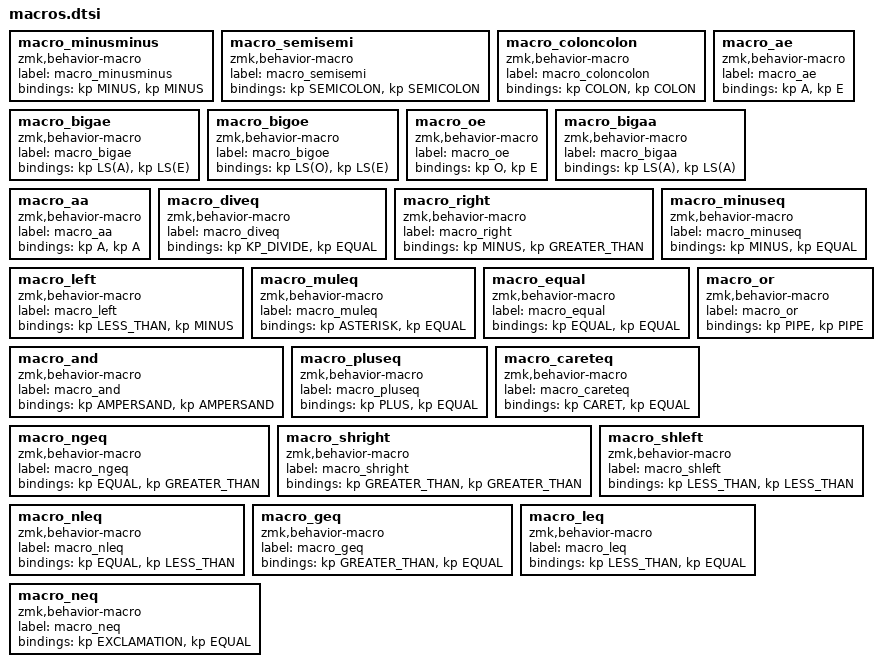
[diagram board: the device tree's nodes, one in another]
macro_minusminus: macro_minusminus{
compatible = "zmk,behavior-macro";
label = "macro_minusminus";
#binding-cells = <0>;
bindings = <&kp MINUS>, <&kp MINUS>;
};
macro_semisemi: macro_semisemi{
compatible = "zmk,behavior-macro";
label = "macro_semisemi";
#binding-cells = <0>;
bindings = <&kp SEMICOLON>, <&kp SEMICOLON>;
};
macro_coloncolon: macro_coloncolon{
compatible = "zmk,behavior-macro";
label = "macro_coloncolon";
#binding-cells = <0>;
bindings = <&kp COLON>, <&kp COLON>;
};
macro_bigae: macro_bigae{
compatible = "zmk,behavior-macro";
label = "macro_bigae";
#binding-cells = <0>;
bindings = <&kp LS(A)>, <&kp LS(E)>;
};
macro_ae: macro_ae{
compatible = "zmk,behavior-macro";
label = "macro_ae";
#binding-cells = <0>;
bindings = <&kp A>, <&kp E>;
};
macro_bigoe: macro_bigoe{
compatible = "zmk,behavior-macro";
label = "macro_bigoe";
#binding-cells = <0>;
bindings = <&kp LS(O)>, <&kp LS(E)>;
};
macro_oe: macro_oe{
compatible = "zmk,behavior-macro";
label = "macro_oe";
#binding-cells = <0>;
bindings = <&kp O>, <&kp E>;
};
macro_bigaa: macro_bigaa{
compatible = "zmk,behavior-macro";
label = "macro_bigaa";
#binding-cells = <0>;
bindings = <&kp LS(A)>, <&kp LS(A)>;
};
macro_aa: macro_aa{
compatible = "zmk,behavior-macro";
label = "macro_aa";
#binding-cells = <0>;
bindings = <&kp A>, <&kp A>;
};
macro_diveq: macro_diveq{
compatible = "zmk,behavior-macro";
label = "macro_diveq";
#binding-cells = <0>;
bindings = <&kp KP_DIVIDE>, <&kp EQUAL>;
};
macro_right: macro_right{
compatible = "zmk,behavior-macro";
label = "macro_right";
#binding-cells = <0>;
bindings = <&kp MINUS>, <&kp GREATER_THAN>;
};
macro_left: macro_left{
compatible = "zmk,behavior-macro";
label = "macro_left";
#binding-cells = <0>;
bindings = <&kp LESS_THAN>, <&kp MINUS>;
};
macro_minuseq: macro_minuseq{
compatible = "zmk,behavior-macro";
label = "macro_minuseq";
#binding-cells = <0>;
bindings = <&kp MINUS>, <&kp EQUAL>;
};
macro_muleq: macro_muleq{
compatible = "zmk,behavior-macro";
label = "macro_muleq";
#binding-cells = <0>;
bindings = <&kp ASTERISK>, <&kp EQUAL>;
};
macro_equal: macro_equal{
compatible = "zmk,behavior-macro";
label = "macro_equal";
#binding-cells = <0>;
bindings = <&kp EQUAL>, <&kp EQUAL>;
};
macro_or: macro_or{
compatible = "zmk,behavior-macro";
label = "macro_or";
#binding-cells = <0>;
bindings = <&kp PIPE>, <&kp PIPE>;
};
macro_and: macro_and{
compatible = "zmk,behavior-macro";
label = "macro_and";
#binding-cells = <0>;
bindings = <&kp AMPERSAND>, <&kp AMPERSAND>;
};
macro_pluseq: macro_pluseq{
compatible = "zmk,behavior-macro";
label = "macro_pluseq";
#binding-cells = <0>;
bindings = <&kp PLUS>, <&kp EQUAL>;
};
macro_careteq: macro_careteq{
compatible = "zmk,behavior-macro";
label = "macro_careteq";
#binding-cells = <0>;
bindings = <&kp CARET>, <&kp EQUAL>;
};
macro_ngeq: macro_ngeq{
compatible = "zmk,behavior-macro";
label = "macro_ngeq";
#binding-cells = <0>;
bindings = <&kp EQUAL>, <&kp GREATER_THAN>;
};
macro_shright: macro_shright{
compatible = "zmk,behavior-macro";
label = "macro_shright";
#binding-cells = <0>;
bindings = <&kp GREATER_THAN>, <&kp GREATER_THAN>;
};
macro_shleft: macro_shleft{
compatible = "zmk,behavior-macro";
label = "macro_shleft";
#binding-cells = <0>;
bindings = <&kp LESS_THAN>, <&kp LESS_THAN>;
};
macro_nleq: macro_nleq{
compatible = "zmk,behavior-macro";
label = "macro_nleq";
#binding-cells = <0>;
bindings = <&kp EQUAL>, <&kp LESS_THAN>;
};
macro_geq: macro_geq{
compatible = "zmk,behavior-macro";
label = "macro_geq";
#binding-cells = <0>;
bindings = <&kp GREATER_THAN>, <&kp EQUAL>;
};
macro_leq: macro_leq{
compatible = "zmk,behavior-macro";
label = "macro_leq";
#binding-cells = <0>;
bindings = <&kp LESS_THAN>, <&kp EQUAL>;
};
macro_neq: macro_neq{
compatible = "zmk,behavior-macro";
label = "macro_neq";
#binding-cells = <0>;
bindings = <&kp EXCLAMATION>, <&kp EQUAL>;
};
